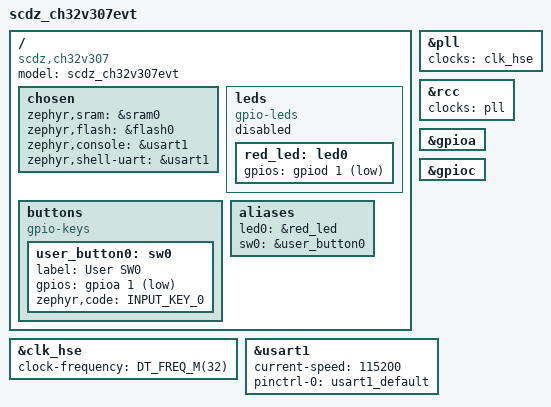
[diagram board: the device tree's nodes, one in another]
/*
 * Copyright (c) 2025 Thomas Boje
 * SPDX-License-Identifier: Apache-2.0
 */

/dts-v1/;

#include <wch/ch32v307/ch32v307vc.dtsi>
#include <zephyr/dt-bindings/gpio/gpio.h>
#include <zephyr/dt-bindings/input/input-event-codes.h>
#include "ch32v307evt-pinctrl.dtsi"

/ {
	model = "scdz_ch32v307evt";
	compatible = "scdz,ch32v307";

	chosen {
		zephyr,sram = &sram0;
		zephyr,flash = &flash0;
		zephyr,console = &usart1;
		zephyr,shell-uart = &usart1;
	};

	leds {
		compatible = "gpio-leds";

		/*
		 * Please connect the unconnected LED1 on the SCDZ CH32V307EVT
		 * board to a suitable GPIO pin (like PD1) and then change
		 * this status to "okay".
		 */
		status = "disabled";

		red_led: led0 {
			gpios = <&gpiod 1 GPIO_ACTIVE_LOW>;
		};
	};
	buttons {
		compatible = "gpio-keys";

		user_button0: sw0 {
			label = "User SW0";
			gpios = <&gpioa 1 (GPIO_ACTIVE_LOW | GPIO_PULL_UP)>;
			zephyr,code = <INPUT_KEY_0>;
		};
	};

	aliases {
		led0 = &red_led;
		sw0 = &user_button0;
	};
};

&clk_hse {
	clock-frequency = <DT_FREQ_M(32)>;
	status = "okay";
};

&pll {
	clocks = <&clk_hse>;
	status = "okay";
};

&rcc {
	clocks = <&pll>;
};


&gpioa {
	status = "okay";
};

&gpioc {
	status = "okay";
};

&usart1 {
	status = "okay";
	current-speed = <115200>;
	pinctrl-0 = <&usart1_default>;
	pinctrl-names = "default";
};
